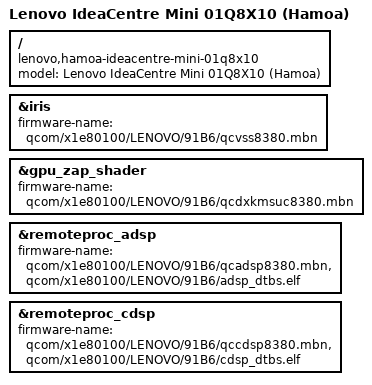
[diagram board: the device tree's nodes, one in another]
// SPDX-License-Identifier: BSD-3-Clause
/*
 * Copyright (c) Qualcomm Technologies, Inc. and/or its subsidiaries.
 */

/dts-v1/;

#include "hamoa.dtsi"
#include "x1-lenovo-ideacentre-mini-01q8x10.dtsi"

/ {
	model = "Lenovo IdeaCentre Mini 01Q8X10 (Hamoa)";
	compatible = "lenovo,hamoa-ideacentre-mini-01q8x10", "lenovo,ideacentre-mini-01q8x10", "qcom,x1e80100";
};

&iris {
	firmware-name = "qcom/x1e80100/LENOVO/91B6/qcvss8380.mbn";

	status = "okay";
};

&gpu_zap_shader {
	firmware-name = "qcom/x1e80100/LENOVO/91B6/qcdxkmsuc8380.mbn";
};

&remoteproc_adsp {
	firmware-name = "qcom/x1e80100/LENOVO/91B6/qcadsp8380.mbn",
			"qcom/x1e80100/LENOVO/91B6/adsp_dtbs.elf";

	status = "okay";
};

&remoteproc_cdsp {
	firmware-name = "qcom/x1e80100/LENOVO/91B6/qccdsp8380.mbn",
			"qcom/x1e80100/LENOVO/91B6/cdsp_dtbs.elf";

	status = "okay";
};

